# WS63 register map
File version: 1.0
CPU: other r0p0, little endian, MPU, FPU, 3 interrupt priority bits
Registers are 32-bit, read-write, reset 0x0 unless marked. A register's access mark holds for its fields unless they carry their own. Offsets are from the block's base; [hi:lo] are bit positions; {n}, {i} and the like mark numbered series.

## SPACC — Security accelerator - AES/SM4/LEA/TDES symmetric crypto, HASH/HMAC
Base 0x44100000
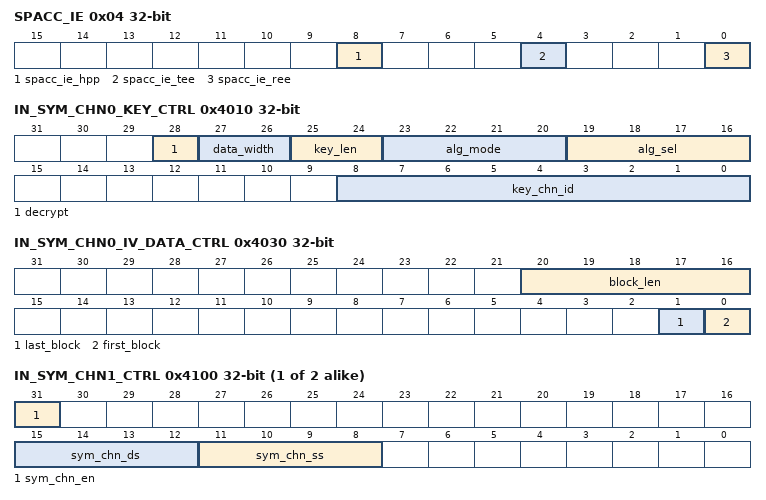
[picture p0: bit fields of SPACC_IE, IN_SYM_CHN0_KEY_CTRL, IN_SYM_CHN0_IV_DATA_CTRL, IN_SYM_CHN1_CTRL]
0x04 SPACC_IE — SPACC interrupt enable
  [8] spacc_ie_hpp — HPP interrupt enable
  [4] spacc_ie_tee — TEE interrupt enable
  [0] spacc_ie_ree — REE interrupt enable
0x08 SPACC_INT_RAW_SYM_CLR_FINISH — Sym clear finish raw interrupt
  [15:0] raw_sym_clr_finish_int write-1-clears — Raw interrupt for sym clear finish; write one to clear
0x14 SPACC_INT_RAW_HASH_CLEAR_FINISH — Hash channel-clear completion status; write one to clear
  [15:0] raw_hash_clear_finish write-1-clears — Hash channel-clear completion bits
0x20 SPACC_SYM_CHN_LOCK — Sym channel lock register
  [31:0] sym_chn_lock — Symmetric channel lock status
0x40 SPACC_HASH_CHN_LOCK — Hash channel lock register
  [31:0] hash_chn_lock — Hash channel lock status
0x60 SPACC_SYM_CHN_CLEAR_REQ wo — Sym channel clear request
  [31:0] sym_chn_clear_req — Clear request for symmetric channels
0x68 SPACC_HASH_CHN_CLEAR_REQ wo — Hash channel clear request
  [31:0] hash_chn_clear_req — Clear request for hash channels
0x200 SPACC_BUS_ERR ro — Bus error register
  [31:0] bus_err — Bus error status
0x4000 IN_SYM_CHN0_CTRL — Sym channel 0 control register (no-DMA mode)
  [31] sym_chn0_req wo — Channel 0 start request
0x4004 IN_SYM_CHN0_SPECIAL_CTRL — Sym channel 0 special control
  [0] sym_chn0_odd_even — Odd/even control for TDES
0x4010 IN_SYM_CHN0_KEY_CTRL — Sym channel 0 key control (no-DMA mode)
  [28] decrypt — Decrypt: 0=encrypt; 1=decrypt
  [27:26] data_width — Data width: 0=128bit; 1=64bit; 2=32bit
    0=Width128 (128-bit data path); 1=Width64 (64-bit data path); 2=Width32 (32-bit data path)
  [25:24] key_len — Key length: 1=128bit; 2=192bit; 3=256bit
    1=Key128 (128-bit key); 2=Key192 (192-bit key); 3=Key256 (256-bit key)
  [23:20] alg_mode — Mode: 1=ECB; 3=CBC; 6=CTR; 0xA=GCM; 0xC=CMAC
    1=ECB (Electronic Codebook); 3=CBC (Cipher Block Chaining); 6=CTR (Counter mode); 7=OFB (Output Feedback); 8=CFB (Cipher Feedback); 9=CCM (CCM authenticated encryption); 10=GCM (Galois/Counter Mode); 11=GCTR (GCM CTR only); 12=CMAC (Cipher-based MAC)
  [19:16] alg_sel — Algorithm: 2=AES; 4=LEA; 5=SM4; 6=GHASH; 7=TDES
    2=AES (AES algorithm); 4=LEA (LEA (Lightweight Encryption Algorithm)); 5=SM4 (SM4 (Chinese national standard)); 6=GHASH (GHASH (GCM authentication)); 7=TDES (Triple DES)
  [8:0] key_chn_id — Key channel ID
0x4030 IN_SYM_CHN0_IV_DATA_CTRL — Sym channel 0 IV/data control (register mode)
  [20:16] block_len — Block length (in bytes)
  [1] last_block — Last block flag
  [0] first_block — First block flag
0x4040 IN_SYM_CHN0_IV0 — Sym channel 0 IV word 0 (register mode)
  [31:0] iv0 — IV[31:0]
{0x4040+4i} IN_SYM_CHN0_IV{i} (i=1..3) — Sym channel 0 IV word {i}
  [31:0] iv{i} — IV[{32i+31}:{32i}]
0x4050 IN_SYM_CHN0_DATA0 — Sym channel 0 data word 0 (register mode)
  [31:0] data0 — Input data[31:0]
{0x4000+0x100*i} IN_SYM_CHN{i}_CTRL (i=1..2) — Symmetric channel {i} control
  [31] sym_chn_en — Enable the symmetric channel
  [15:12] sym_chn_ds — Destination security selector; 0xA selects non-secure REE
  [11:8] sym_chn_ss — Source security selector; 0xA selects non-secure REE
{0x4004+0x100*i} IN_SYM_OUT_CTRL{i} (i=1..2) — Symmetric channel {i} output control
  [0] dma_copy — Enable DMA copy mode
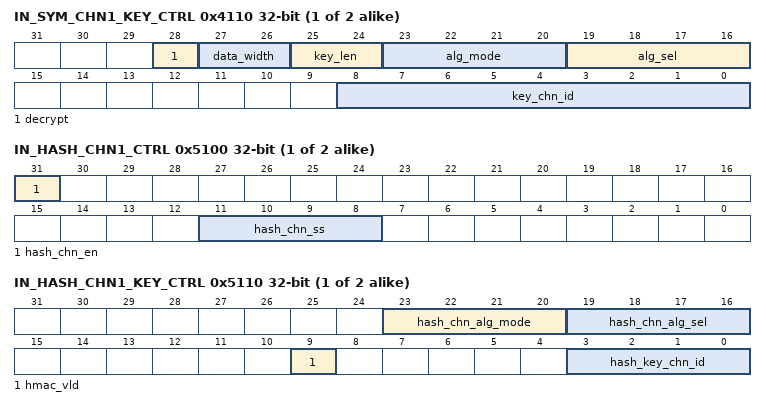
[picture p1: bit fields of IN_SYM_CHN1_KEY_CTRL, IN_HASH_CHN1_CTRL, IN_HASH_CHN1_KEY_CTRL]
{0x4010+0x100*i} IN_SYM_CHN{i}_KEY_CTRL (i=1..2) — Symmetric channel {i} algorithm and keyslot control
  [28] decrypt — Decrypt when set
  [27:26] data_width — Data width: 0=128bit; 1=64bit; 2=32bit
  [25:24] key_len — Key length: 1=128bit; 2=192bit; 3=256bit
  [23:20] alg_mode — Mode: 1=ECB; 3=CBC; 6=CTR; 0xC=CMAC
  [19:16] alg_sel — Algorithm: 2=AES; 5=SM4
  [8:0] key_chn_id — MCipher keyslot ID
{0x4020+0x100*i} IN_SYM_CHN{i}_NODE_START_ADDR_H (i=1..2) — Symmetric input descriptor-list address bits 35:32
  [3:0] address_high — Address bits 35:32
{0x4024+0x100*i} IN_SYM_CHN{i}_NODE_START_ADDR_L (i=1..2) — Symmetric input descriptor-list address bits 31:0
  [31:0] address_low — Address bits 31:0
{0x402C+0x100*i} IN_SYM_CHN{i}_NODE_LENGTH (i=1..2) — Symmetric input descriptor ring depth
  [7:0] node_length — Descriptor count
{0x4030+0x100*i} IN_SYM_CHN{i}_NODE_WR_POINT (i=1..2) — Symmetric input descriptor producer pointer
  [7:0] write_pointer — Producer index
{0x4034+0x100*i} IN_SYM_CHN{i}_NODE_RD_POINT (i=1..2) ro — Symmetric input descriptor consumer pointer
  [7:0] read_pointer — Consumer index
{0x5000+0x100*i} IN_HASH_CHN{i}_CTRL (i=1..2) — Hash channel {i} control
  [31] hash_chn_en — Enable the hash channel
  [11:8] hash_chn_ss — Security-source selector; 0xA selects non-secure REE
{0x5010+0x100*i} IN_HASH_CHN{i}_KEY_CTRL (i=1..2) — Hash channel {i} algorithm and keyslot control
  [23:20] hash_chn_alg_mode — SHA-2 mode: 0=224; 1=256; 2=384; 3=512
  [19:16] hash_chn_alg_sel — Hash family: 0xA=SHA-1; 0xB=SHA-2; 0xC=SM3
  [9] hmac_vld — Use the selected HMAC keyslot
  [3:0] hash_key_chn_id — HMAC keyslot channel ID
{0x5020+0x100*i} IN_HASH_CHN{i}_NODE_START_ADDR_H (i=1..2) — Hash channel {i} descriptor-list address bits 35:32
  [3:0] address_high — Descriptor-list address bits 35:32
{0x5024+0x100*i} IN_HASH_CHN{i}_NODE_START_ADDR_L (i=1..2) — Hash channel {i} descriptor-list address bits 31:0
  [31:0] address_low — Descriptor-list address bits 31:0
{0x502C+0x100*i} IN_HASH_CHN{i}_NODE_LENGTH (i=1..2) — Hash channel {i} descriptor ring depth
  [7:0] node_length — Number of descriptors in the ring
{0x5030+0x100*i} IN_HASH_CHN{i}_NODE_WR_POINT (i=1..2) — Hash channel {i} descriptor write pointer
  [7:0] write_pointer — Descriptor producer index
{0x5034+0x100*i} IN_HASH_CHN{i}_NODE_RD_POINT (i=1..2) ro — Hash channel {i} descriptor read pointer
  [7:0] read_pointer — Descriptor consumer index
{0x50C0+0x100*i} IN_HASH_CHN{i}_DATA_LEN (i=1..2) ro — Hash channel {i} unprocessed byte count
  [31:0] data_len — Bytes not yet consumed by the engine
0x8070 REE_SYM_CALC_CTRL_CHECK_ERR ro — REE symmetric-control validation error summary
  [31:0] error — Non-zero when symmetric channel validation failed
0x8074 REE_SYM_CALC_CTRL_CHECK_ERR_STATUS ro — REE symmetric-control validation error detail
  [31:0] status — Validation error detail
0x8078 REE_HASH_CALC_CTRL_CHECK_ERR ro — REE hash-control validation error summary
  [31:0] error — Non-zero when hash channel control validation failed
0x807C REE_HASH_CALC_CTRL_CHECK_ERR_STATUS ro — REE hash-control validation error detail
  [31:0] status — Hash-control validation error detail
0x8600 HASH_CHANN_RAW_INT — Hash channel completion status; write one to clear
  [15:0] hash_chann_raw_int write-1-clears — Completion bits for hash channels 0 through 15
0x8604 HASH_CHANN_RAW_INT_EN — Hash channel completion interrupt enable
  [15:0] hash_chann_raw_int_en — Interrupt-enable bits for hash channels 0 through 15
0x8610 SYM_CHANN_RAW_INT — Sym channel raw interrupt status; write one to clear
  [15:0] sym_chann_raw_int write-1-clears — Raw interrupt per channel [15:0]
{0xA000+0x80*i} CHANN{i}_HASH_STATE_VAL (i=1..2) — Hash channel {i} indexed state data
  [31:0] state — State word selected by the state address register
{0xA004+0x80*i} CHANN{i}_HASH_STATE_VAL_ADDR (i=1..2) — Hash channel {i} state-word selector
  [4:0] index — State word index
0xC000 OUT_SYM_CHAN_RAW_LAST_NODE_INT — Output last-node completion status; write one to clear
  [15:0] out_sym_chan_raw_int write-1-clears — Completion bits for symmetric channels
{0xCF20+0x100*i} OUT_SYM_CHN{i}_NODE_START_ADDR_H (i=1..2) — Symmetric output descriptor-list address bits 35:32
  [3:0] address_high — Address bits 35:32
{0xCF24+0x100*i} OUT_SYM_CHN{i}_NODE_START_ADDR_L (i=1..2) — Symmetric output descriptor-list address bits 31:0
  [31:0] address_low — Address bits 31:0
{0xCF28+0x100*i} OUT_SYM_CHN{i}_NODE_LENGTH (i=1..2) — Symmetric output descriptor ring depth
  [7:0] node_length — Descriptor count
{0xCF30+0x100*i} OUT_SYM_CHN{i}_NODE_WR_POINT (i=1..2) — Symmetric output descriptor producer pointer
  [7:0] write_pointer — Producer index
{0xCF34+0x100*i} OUT_SYM_CHN{i}_NODE_RD_POINT (i=1..2) ro — Symmetric output descriptor consumer pointer
  [7:0] read_pointer — Consumer index
